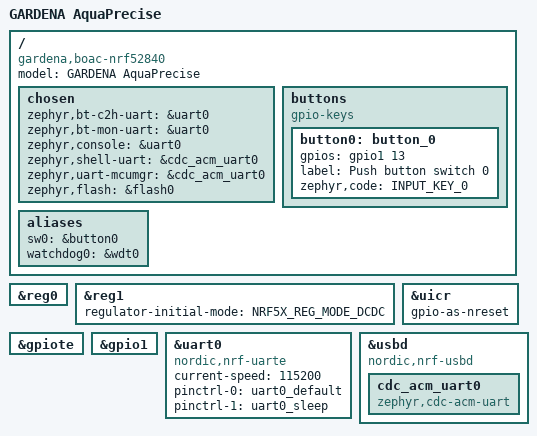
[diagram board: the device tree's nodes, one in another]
/*
 * Copyright (c) 2025 Reto Schneider
 *
 * SPDX-License-Identifier: Apache-2.0
 */

/dts-v1/;
#include <nordic/nrf52840_qiaa.dtsi>
#include <nordic/nrf52840_partition.dtsi>
#include "boac-pinctrl.dtsi"

/ {
	model = "GARDENA AquaPrecise";
	compatible = "gardena,boac-nrf52840", "nordic,nrf52840";

	chosen {
		zephyr,bt-c2h-uart = &uart0;
		zephyr,bt-mon-uart = &uart0;
		zephyr,console = &uart0;
		zephyr,shell-uart = &cdc_acm_uart0;
		zephyr,uart-mcumgr = &cdc_acm_uart0;
    zephyr,flash = &flash0;
	};

	buttons {
		compatible = "gpio-keys";
		button0: button_0 {
			gpios = <&gpio1 13 (GPIO_ACTIVE_HIGH)>;
			label = "Push button switch 0";
			zephyr,code = <INPUT_KEY_0>;
		};
	};

	/* These aliases are provided for compatibility with samples */
	aliases {
		sw0 = &button0;
		watchdog0 = &wdt0;
	};
};

&reg0 {
	status = "okay";
};

&reg1 {
	regulator-initial-mode = <NRF5X_REG_MODE_DCDC>;
};

&uicr {
	gpio-as-nreset;
};

&gpiote {
	status = "okay";
};

&gpio1 {
	status = "okay";
};

&uart0 {
	compatible = "nordic,nrf-uarte";
	status = "okay";
	current-speed = <115200>;
	pinctrl-0 = <&uart0_default>;
	pinctrl-1 = <&uart0_sleep>;
	pinctrl-names = "default", "sleep";
};

zephyr_udc0: &usbd {
	compatible = "nordic,nrf-usbd";
	status = "okay";
	cdc_acm_uart0: cdc_acm_uart0 {
		compatible = "zephyr,cdc-acm-uart";
	};
};
